VERSION ""

NS_ :

BS_:

BU_: FrontRadar FCM
VAL_TABLE_ VSig_Neighbor_type 8 "Barrier" 7 "Botts dots" 6 "DLM inner undecided" 5 "DLM inner dashed" 4 "DLM inner solid" 3 "Road Edge" 2 "Undecided" 1 "Solid" 0 "Dashed" ;
VAL_TABLE_ Motion_Status 4 "Moving Slowly" 3 "Stopped" 2 "Stationary" 1 "Moving" 0 "Unknown" ;

BO_ 3221225472 VECTOR__INDEPENDENT_SIG_MSG: 0 Vector__XXX
 SG_ CAN_TX_TRACK_ROLLING_COUNT : 0|1@0+ (1,0) [0|1] "" Vector__XXX
 SG_ CAN_TX_TRACK_RANGE_RATE : 0|14@0- (0.01,0) [-81.92|81.91] "m/s" Vector__XXX
 SG_ CAN_TX_TRACK_RANGE_ACCEL : 0|10@0- (0.05,0) [-25.6|25.55] "m/s/s" Vector__XXX
 SG_ CAN_TX_TRACK_ANGLE : 0|10@0- (0.1,0) [-51.2|51.1] "deg" Vector__XXX
 SG_ CAN_TX_TRACK_RANGE : 0|11@0+ (0.1,0) [0|204.7] "m" Vector__XXX

BO_ 623 ME_Lane_Additional_Data_3: 8 FCM
 SG_ Rh_Neighbor_LaneMark_Pos_C0 : 15|11@0+ (0.01,-10) [-10|10] "" Vector__XXX

BO_ 622 ME_Lane_Additional_Data_2: 8 FCM
 SG_ Lh_Neighbor_LaneMark_Pos_C0 : 15|11@0+ (0.01,-10) [-10|10] "" Vector__XXX

BO_ 621 ME_Lane_Additional_Data_1: 8 FCM
 SG_ Rh_Neightbor_Type : 15|4@0+ (1,0) [0|0] "" Vector__XXX
 SG_ Lh_Neightbor_Type : 7|4@0+ (1,0) [0|0] "" Vector__XXX

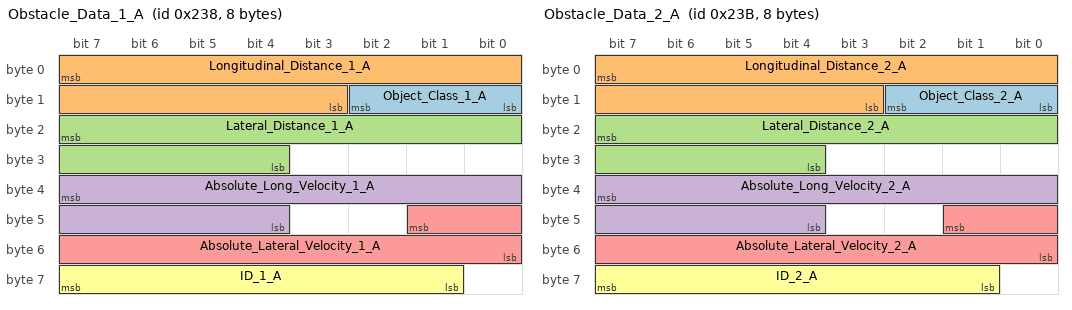
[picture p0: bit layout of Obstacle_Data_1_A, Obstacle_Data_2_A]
BO_ 568 Obstacle_Data_1_A: 8 FCM
 SG_ Object_Class_1_A : 10|3@0+ (1,0) [0|6] "-"  FrontRadar
 SG_ Longitudinal_Distance_1_A : 7|13@0+ (0.05,0) [0|350] "m"  FrontRadar
 SG_ Lateral_Distance_1_A : 23|12@0+ (0.05,-102.4) [-102.4|102.35] "m"  FrontRadar
 SG_ Absolute_Long_Velocity_1_A : 39|12@0+ (0.05,-100) [-100|100] "m/s"  FrontRadar
 SG_ Absolute_Lateral_Velocity_1_A : 41|10@0+ (0.05,-25) [-25|25] "m/s"  FrontRadar
 SG_ ID_1_A : 63|7@0+ (1,0) [0|127] "-"  FrontRadar

BO_ 569 Obstacle_Data_1_B: 8 FCM
 SG_ Motion_Status_1_B : 26|3@0+ (1,0) [0|4] "-"  FrontRadar

BO_ 570 Obstacle_Data_1_C: 8 FCM
 SG_ Object_Age_1_C : 39|11@0+ (1,0) [0|2047] "Frame"  FrontRadar

BO_ 571 Obstacle_Data_2_A: 8 FCM
 SG_ Object_Class_2_A : 10|3@0+ (1,0) [0|6] "-"  FrontRadar
 SG_ Longitudinal_Distance_2_A : 7|13@0+ (0.05,0) [0|350] "m"  FrontRadar
 SG_ Lateral_Distance_2_A : 23|12@0+ (0.05,-102.4) [-102.4|102.35] "m"  FrontRadar
 SG_ Absolute_Long_Velocity_2_A : 39|12@0+ (0.05,-100) [-100|100] "m/s"  FrontRadar
 SG_ Absolute_Lateral_Velocity_2_A : 41|10@0+ (0.05,-25) [-25|25] "m/s"  FrontRadar
 SG_ ID_2_A : 63|7@0+ (1,0) [0|127] "-"  FrontRadar

BO_ 572 Obstacle_Data_2_B: 8 FCM
 SG_ Motion_Status_2_B : 26|3@0+ (1,0) [0|4] "-"  FrontRadar

BO_ 573 Obstacle_Data_2_C: 8 FCM
 SG_ Object_Age_2_C : 39|11@0+ (1,0) [0|2047] "Frame"  FrontRadar

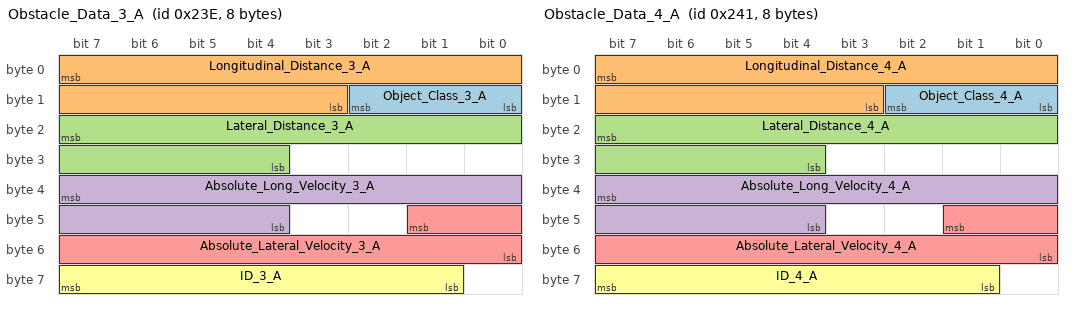
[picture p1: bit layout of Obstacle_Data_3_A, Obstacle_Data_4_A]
BO_ 574 Obstacle_Data_3_A: 8 FCM
 SG_ Object_Class_3_A : 10|3@0+ (1,0) [0|6] "-"  FrontRadar
 SG_ Longitudinal_Distance_3_A : 7|13@0+ (0.05,0) [0|350] "m"  FrontRadar
 SG_ Lateral_Distance_3_A : 23|12@0+ (0.05,-102.4) [-102.4|102.35] "m"  FrontRadar
 SG_ Absolute_Long_Velocity_3_A : 39|12@0+ (0.05,-100) [-100|100] "m/s"  FrontRadar
 SG_ Absolute_Lateral_Velocity_3_A : 41|10@0+ (0.05,-25) [-25|25] "m/s"  FrontRadar
 SG_ ID_3_A : 63|7@0+ (1,0) [0|127] "-"  FrontRadar

BO_ 575 Obstacle_Data_3_B: 8 FCM
 SG_ Motion_Status_3_B : 26|3@0+ (1,0) [0|4] "-"  FrontRadar

BO_ 576 Obstacle_Data_3_C: 8 FCM
 SG_ Object_Age_3_C : 39|11@0+ (1,0) [0|2047] "Frame"  FrontRadar

BO_ 577 Obstacle_Data_4_A: 8 FCM
 SG_ Object_Class_4_A : 10|3@0+ (1,0) [0|6] "-"  FrontRadar
 SG_ Longitudinal_Distance_4_A : 7|13@0+ (0.05,0) [0|350] "m"  FrontRadar
 SG_ Lateral_Distance_4_A : 23|12@0+ (0.05,-102.4) [-102.4|102.35] "m"  FrontRadar
 SG_ Absolute_Long_Velocity_4_A : 39|12@0+ (0.05,-100) [-100|100] "m/s"  FrontRadar
 SG_ Absolute_Lateral_Velocity_4_A : 41|10@0+ (0.05,-25) [-25|25] "m/s"  FrontRadar
 SG_ ID_4_A : 63|7@0+ (1,0) [0|127] "-"  FrontRadar

BO_ 578 Obstacle_Data_4_B: 8 FCM
 SG_ Motion_Status_4_B : 26|3@0+ (1,0) [0|4] "-"  FrontRadar

BO_ 579 Obstacle_Data_4_C: 8 FCM
 SG_ Object_Age_4_C : 39|11@0+ (1,0) [0|2047] "Frame"  FrontRadar

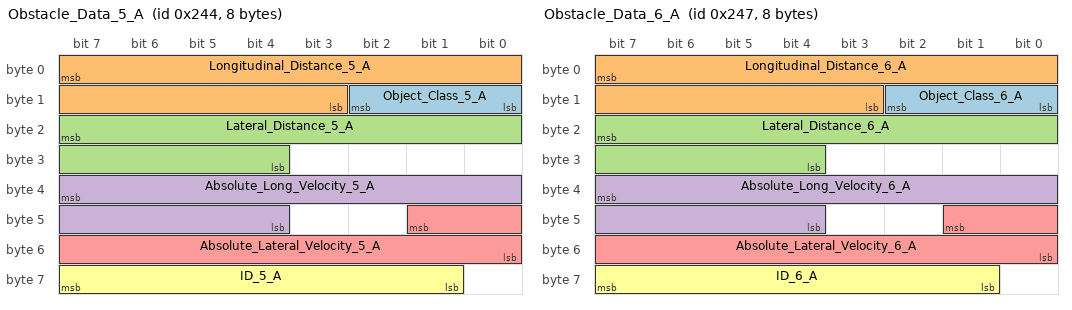
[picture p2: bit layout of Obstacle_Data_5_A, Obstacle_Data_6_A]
BO_ 580 Obstacle_Data_5_A: 8 FCM
 SG_ Object_Class_5_A : 10|3@0+ (1,0) [0|6] "-"  FrontRadar
 SG_ Longitudinal_Distance_5_A : 7|13@0+ (0.05,0) [0|350] "m"  FrontRadar
 SG_ Lateral_Distance_5_A : 23|12@0+ (0.05,-102.4) [-102.4|102.35] "m"  FrontRadar
 SG_ Absolute_Long_Velocity_5_A : 39|12@0+ (0.05,-100) [-100|100] "m/s"  FrontRadar
 SG_ Absolute_Lateral_Velocity_5_A : 41|10@0+ (0.05,-25) [-25|25] "m/s"  FrontRadar
 SG_ ID_5_A : 63|7@0+ (1,0) [0|127] "-"  FrontRadar

BO_ 581 Obstacle_Data_5_B: 8 FCM
 SG_ Motion_Status_5_B : 26|3@0+ (1,0) [0|4] "-"  FrontRadar

BO_ 582 Obstacle_Data_5_C: 8 FCM
 SG_ Object_Age_5_C : 39|11@0+ (1,0) [0|2047] "Frame"  FrontRadar

BO_ 583 Obstacle_Data_6_A: 8 FCM
 SG_ Object_Class_6_A : 10|3@0+ (1,0) [0|6] "-"  FrontRadar
 SG_ Longitudinal_Distance_6_A : 7|13@0+ (0.05,0) [0|350] "m"  FrontRadar
 SG_ Lateral_Distance_6_A : 23|12@0+ (0.05,-102.4) [-102.4|102.35] "m"  FrontRadar
 SG_ Absolute_Long_Velocity_6_A : 39|12@0+ (0.05,-100) [-100|100] "m/s"  FrontRadar
 SG_ Absolute_Lateral_Velocity_6_A : 41|10@0+ (0.05,-25) [-25|25] "m/s"  FrontRadar
 SG_ ID_6_A : 63|7@0+ (1,0) [0|127] "-"  FrontRadar

BO_ 584 Obstacle_Data_6_B: 8 FCM
 SG_ Motion_Status_6_B : 26|3@0+ (1,0) [0|4] "-"  FrontRadar

BO_ 585 Obstacle_Data_6_C: 8 FCM
 SG_ Object_Age_6_C : 39|11@0+ (1,0) [0|2047] "Frame"  FrontRadar

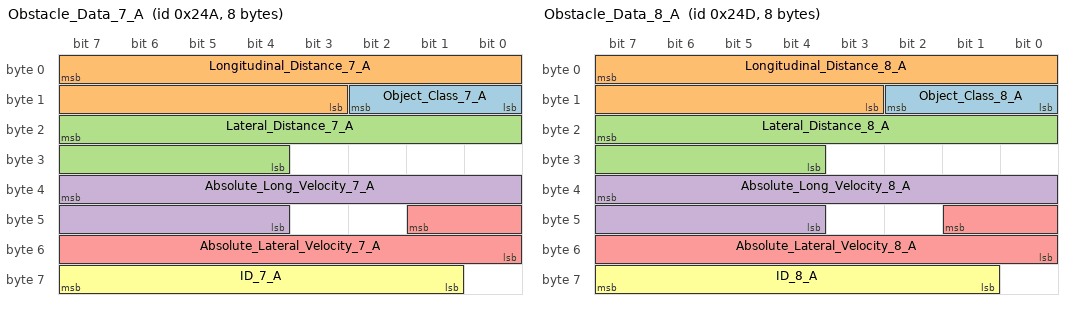
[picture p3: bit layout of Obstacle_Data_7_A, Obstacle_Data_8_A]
BO_ 586 Obstacle_Data_7_A: 8 FCM
 SG_ Object_Class_7_A : 10|3@0+ (1,0) [0|6] "-"  FrontRadar
 SG_ Longitudinal_Distance_7_A : 7|13@0+ (0.05,0) [0|350] "m"  FrontRadar
 SG_ Lateral_Distance_7_A : 23|12@0+ (0.05,-102.4) [-102.4|102.35] "m"  FrontRadar
 SG_ Absolute_Long_Velocity_7_A : 39|12@0+ (0.05,-100) [-100|100] "m/s"  FrontRadar
 SG_ Absolute_Lateral_Velocity_7_A : 41|10@0+ (0.05,-25) [-25|25] "m/s"  FrontRadar
 SG_ ID_7_A : 63|7@0+ (1,0) [0|127] "-"  FrontRadar

BO_ 587 Obstacle_Data_7_B: 8 FCM
 SG_ Motion_Status_7_B : 26|3@0+ (1,0) [0|4] "-"  FrontRadar

BO_ 588 Obstacle_Data_7_C: 8 FCM
 SG_ Object_Age_7_C : 39|11@0+ (1,0) [0|2047] "Frame"  FrontRadar

BO_ 589 Obstacle_Data_8_A: 8 FCM
 SG_ Object_Class_8_A : 10|3@0+ (1,0) [0|6] "-"  FrontRadar
 SG_ Longitudinal_Distance_8_A : 7|13@0+ (0.05,0) [0|350] "m"  FrontRadar
 SG_ Lateral_Distance_8_A : 23|12@0+ (0.05,-102.4) [-102.4|102.35] "m"  FrontRadar
 SG_ Absolute_Long_Velocity_8_A : 39|12@0+ (0.05,-100) [-100|100] "m/s"  FrontRadar
 SG_ Absolute_Lateral_Velocity_8_A : 41|10@0+ (0.05,-25) [-25|25] "m/s"  FrontRadar
 SG_ ID_8_A : 63|7@0+ (1,0) [0|127] "-"  FrontRadar

BO_ 590 Obstacle_Data_8_B: 8 FCM
 SG_ Motion_Status_8_B : 26|3@0+ (1,0) [0|4] "-"  FrontRadar

BO_ 591 Obstacle_Data_8_C: 8 FCM
 SG_ Object_Age_8_C : 39|11@0+ (1,0) [0|2047] "Frame"  FrontRadar

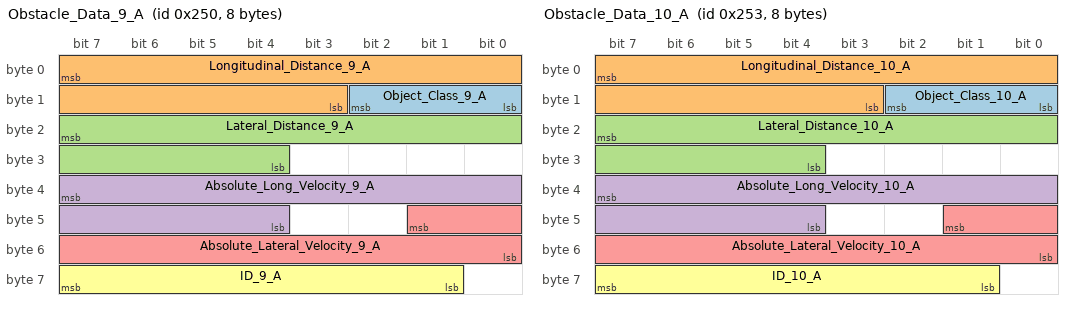
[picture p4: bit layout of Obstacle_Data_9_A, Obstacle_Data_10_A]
BO_ 592 Obstacle_Data_9_A: 8 FCM
 SG_ Object_Class_9_A : 10|3@0+ (1,0) [0|6] "-"  FrontRadar
 SG_ Longitudinal_Distance_9_A : 7|13@0+ (0.05,0) [0|350] "m"  FrontRadar
 SG_ Lateral_Distance_9_A : 23|12@0+ (0.05,-102.4) [-102.4|102.35] "m"  FrontRadar
 SG_ Absolute_Long_Velocity_9_A : 39|12@0+ (0.05,-100) [-100|100] "m/s"  FrontRadar
 SG_ Absolute_Lateral_Velocity_9_A : 41|10@0+ (0.05,-25) [-25|25] "m/s"  FrontRadar
 SG_ ID_9_A : 63|7@0+ (1,0) [0|127] "-"  FrontRadar

BO_ 593 Obstacle_Data_9_B: 8 FCM
 SG_ Motion_Status_9_B : 26|3@0+ (1,0) [0|4] "-"  FrontRadar

BO_ 594 Obstacle_Data_9_C: 8 FCM
 SG_ Object_Age_9_C : 39|11@0+ (1,0) [0|2047] "Frame"  FrontRadar

BO_ 595 Obstacle_Data_10_A: 8 FCM
 SG_ Object_Class_10_A : 10|3@0+ (1,0) [0|6] "-"  FrontRadar
 SG_ Longitudinal_Distance_10_A : 7|13@0+ (0.05,0) [0|350] "m"  FrontRadar
 SG_ Lateral_Distance_10_A : 23|12@0+ (0.05,-102.4) [-102.4|102.35] "m"  FrontRadar
 SG_ Absolute_Long_Velocity_10_A : 39|12@0+ (0.05,-100) [-100|100] "m/s"  FrontRadar
 SG_ Absolute_Lateral_Velocity_10_A : 41|10@0+ (0.05,-25) [-25|25] "m/s"  FrontRadar
 SG_ ID_10_A : 63|7@0+ (1,0) [0|127] "-"  FrontRadar

BO_ 596 Obstacle_Data_10_B: 8 FCM
 SG_ Motion_Status_10_B : 26|3@0+ (1,0) [0|4] "-"  FrontRadar

BO_ 597 Obstacle_Data_10_C: 8 FCM
 SG_ Object_Age_10_C : 39|11@0+ (1,0) [0|2047] "Frame"  FrontRadar

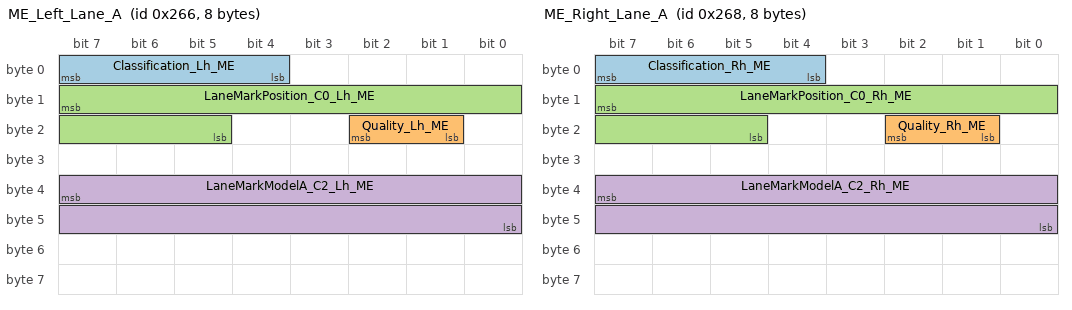
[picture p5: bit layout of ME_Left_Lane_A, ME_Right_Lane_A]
BO_ 614 ME_Left_Lane_A: 8 FCM
 SG_ Classification_Lh_ME : 7|4@0+ (1,0) [0|8] "" Vector__XXX
 SG_ Quality_Lh_ME : 18|2@0+ (1,0) [0|3] ""  FrontRadar
 SG_ LaneMarkPosition_C0_Lh_ME : 15|11@0+ (0.01,-10) [-10|10] "m"  FrontRadar
 SG_ LaneMarkModelA_C2_Lh_ME : 39|16@0+ (9.77E-007,-0.032) [-0.032|0.032] "1/m"  FrontRadar

BO_ 615 ME_Left_Lane_B: 8 FCM
 SG_ LaneMarkHeadingAngle_C1_Lh_ME : 7|10@0+ (0.000977,-0.357) [-0.357|0.357] "rad"  FrontRadar
 SG_ LaneMarkModelDerivA_C3_Lh_ME : 39|16@0+ (3.73E-009,-0.000122) [-0.000122|0.000122] "1/m2"  FrontRadar

BO_ 616 ME_Right_Lane_A: 8 FCM
 SG_ Classification_Rh_ME : 7|4@0+ (1,0) [0|8] "" Vector__XXX
 SG_ Quality_Rh_ME : 18|2@0+ (1,0) [0|3] ""  FrontRadar
 SG_ LaneMarkPosition_C0_Rh_ME : 15|11@0+ (0.01,-10) [-10|10] "m"  FrontRadar
 SG_ LaneMarkModelA_C2_Rh_ME : 39|16@0+ (9.77E-007,-0.032) [-0.032|0.032] "1/m"  FrontRadar

BO_ 617 ME_Right_Lane_B: 8 FCM
 SG_ LaneMarkHeadingAngle_C1_Rh_ME : 7|10@0+ (0.000977,-0.357) [-0.357|0.357] "rad"  FrontRadar
 SG_ LaneMarkModelDerivA_C3_Rh_ME : 39|16@0+ (3.73E-009,-0.000122) [-0.000122|0.000122] "1/m2"  FrontRadar

CM_ "This Private CAN Network Between the FCM and FRM";
CM_ BO_ 3221225472 "This is a message for not used signals, created by Vector CANdb++ DBC OLE DB Provider.";
BA_DEF_ BO_  "GenMsgCycleTime" INT 0 2000;
BA_DEF_DEF_  "GenMsgCycleTime" 0;
BA_ "GenMsgCycleTime" BO_ 568 30;
BA_ "GenMsgCycleTime" BO_ 569 30;
BA_ "GenMsgCycleTime" BO_ 570 30;
BA_ "GenMsgCycleTime" BO_ 571 30;
BA_ "GenMsgCycleTime" BO_ 572 30;
BA_ "GenMsgCycleTime" BO_ 573 30;
BA_ "GenMsgCycleTime" BO_ 574 30;
BA_ "GenMsgCycleTime" BO_ 575 30;
BA_ "GenMsgCycleTime" BO_ 576 30;
BA_ "GenMsgCycleTime" BO_ 577 30;
BA_ "GenMsgCycleTime" BO_ 578 30;
BA_ "GenMsgCycleTime" BO_ 579 30;
BA_ "GenMsgCycleTime" BO_ 580 30;
BA_ "GenMsgCycleTime" BO_ 581 30;
BA_ "GenMsgCycleTime" BO_ 582 30;
BA_ "GenMsgCycleTime" BO_ 583 30;
BA_ "GenMsgCycleTime" BO_ 584 30;
BA_ "GenMsgCycleTime" BO_ 585 30;
BA_ "GenMsgCycleTime" BO_ 586 30;
BA_ "GenMsgCycleTime" BO_ 587 30;
BA_ "GenMsgCycleTime" BO_ 588 30;
BA_ "GenMsgCycleTime" BO_ 589 30;
BA_ "GenMsgCycleTime" BO_ 590 30;
BA_ "GenMsgCycleTime" BO_ 591 30;
BA_ "GenMsgCycleTime" BO_ 592 30;
BA_ "GenMsgCycleTime" BO_ 593 30;
BA_ "GenMsgCycleTime" BO_ 594 30;
BA_ "GenMsgCycleTime" BO_ 595 30;
BA_ "GenMsgCycleTime" BO_ 596 30;
BA_ "GenMsgCycleTime" BO_ 597 30;
BA_ "GenMsgCycleTime" BO_ 614 30;
BA_ "GenMsgCycleTime" BO_ 615 30;
BA_ "GenMsgCycleTime" BO_ 616 30;
BA_ "GenMsgCycleTime" BO_ 617 30;
VAL_ 621 Rh_Neightbor_Type 8 "Barrier" 7 "Botts dots" 6 "DLM inner undecided" 5 "DLM inner dashed" 4 "DLM inner solid" 3 "Road Edge" 2 "Undecided" 1 "Solid" 0 "Dashed" ;
VAL_ 621 Lh_Neightbor_Type 8 "Barrier" 7 "Botts dots" 6 "DLM inner undecided" 5 "DLM inner dashed" 4 "DLM inner solid" 3 "Road Edge" 2 "Undecided" 1 "Solid" 0 "Dashed" ;
VAL_ 568 Object_Class_1_A 0 " Unknown" 1 " Truck" 2 " Car" 3 " MotorBike" 4 " Bicycle" 5 " Pedestrians" 6 " Undecided" ;
VAL_ 569 Motion_Status_1_B 4 "Moving Slowly" 3 "Stopped" 2 "Stationary" 1 "Moving" 0 "Unknown" ;
VAL_ 571 Object_Class_2_A 0 " Unknown" 1 " Truck" 2 " Car" 3 " MotorBike" 4 " Bicycle" 5 " Pedestrians" 6 " Undecided" ;
VAL_ 572 Motion_Status_2_B 4 "Moving Slowly" 3 "Stopped" 2 "Stationary" 1 "Moving" 0 "Unknown" ;
VAL_ 574 Object_Class_3_A 0 " Unknown" 1 " Truck" 2 " Car" 3 " MotorBike" 4 " Bicycle" 5 " Pedestrians" 6 " Undecided" ;
VAL_ 575 Motion_Status_3_B 4 "Moving Slowly" 3 "Stopped" 2 "Stationary" 1 "Moving" 0 "Unknown" ;
VAL_ 577 Object_Class_4_A 0 " Unknown" 1 " Truck" 2 " Car" 3 " MotorBike" 4 " Bicycle" 5 " Pedestrians" 6 " Undecided" ;
VAL_ 578 Motion_Status_4_B 4 "Moving Slowly" 3 "Stopped" 2 "Stationary" 1 "Moving" 0 "Unknown" ;
VAL_ 580 Object_Class_5_A 0 " Unknown" 1 " Truck" 2 " Car" 3 " MotorBike" 4 " Bicycle" 5 " Pedestrians" 6 " Undecided" ;
VAL_ 581 Motion_Status_5_B 4 "Moving Slowly" 3 "Stopped" 2 "Stationary" 1 "Moving" 0 "Unknown" ;
VAL_ 583 Object_Class_6_A 0 " Unknown" 1 " Truck" 2 " Car" 3 " MotorBike" 4 " Bicycle" 5 " Pedestrians" 6 " Undecided" ;
VAL_ 584 Motion_Status_6_B 4 "Moving Slowly" 3 "Stopped" 2 "Stationary" 1 "Moving" 0 "Unknown" ;
VAL_ 586 Object_Class_7_A 0 " Unknown" 1 " Truck" 2 " Car" 3 " MotorBike" 4 " Bicycle" 5 " Pedestrians" 6 " Undecided" ;
VAL_ 587 Motion_Status_7_B 4 "Moving Slowly" 3 "Stopped" 2 "Stationary" 1 "Moving" 0 "Unknown" ;
VAL_ 589 Object_Class_8_A 0 " Unknown" 1 " Truck" 2 " Car" 3 " MotorBike" 4 " Bicycle" 5 " Pedestrians" 6 " Undecided" ;
VAL_ 590 Motion_Status_8_B 4 "Moving Slowly" 3 "Stopped" 2 "Stationary" 1 "Moving" 0 "Unknown" ;
VAL_ 592 Object_Class_9_A 0 " Unknown" 1 " Truck" 2 " Car" 3 " MotorBike" 4 " Bicycle" 5 " Pedestrians" 6 " Undecided" ;
VAL_ 593 Motion_Status_9_B 4 "Moving Slowly" 3 "Stopped" 2 "Stationary" 1 "Moving" 0 "Unknown" ;
VAL_ 595 Object_Class_10_A 0 " Unknown" 1 " Truck" 2 " Car" 3 " MotorBike" 4 " Bicycle" 5 " Pedestrians" 6 " Undecided" ;
VAL_ 596 Motion_Status_10_B 4 "Moving Slowly" 3 "Stopped" 2 "Stationary" 1 "Moving" 0 "Unknown" ;
VAL_ 614 Classification_Lh_ME 8 "Barrier" 7 "Botts Dots" 6 "DLM Inner Undecided" 5 "DLM Inner Dashed" 4 "DLM Inner Solid" 3 "Road Edge" 2 "Undecided" 1 "Solid" 0 "Dashed" ;
VAL_ 614 Quality_Lh_ME 0 " Very Low Quality" 1 " Low Quality" 2 " Prediction" 3 " High Quality" ;
VAL_ 616 Classification_Rh_ME 8 "Barrier" 7 "Botts Dots" 6 "DLM Inner Undecided" 5 "DLM Inner Dashed" 4 "DLM Inner Solid" 3 "Road Edge" 2 "Undecided" 1 "Solid" 0 "Dashed" ;
VAL_ 616 Quality_Rh_ME 0 " Very Low Quality" 1 " Low Quality" 2 " Prediction" 3 " High Quality" ;
